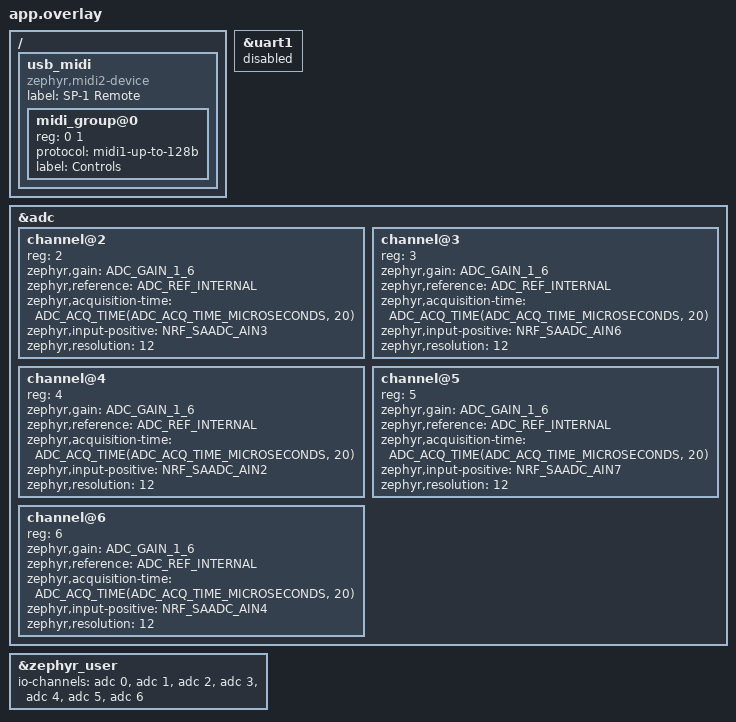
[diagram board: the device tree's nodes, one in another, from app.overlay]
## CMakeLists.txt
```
cmake_minimum_required(VERSION 3.20.0)
find_package(Zephyr REQUIRED HINTS $ENV{ZEPHYR_BASE})
project(sp1-remote)

# Provides sample_usbd_init_device() and friends. Required: with
# CONFIG_CDC_ACM_SERIAL_INITIALIZE_AT_BOOT=n nothing brings USB up on its
# own, so without this the diagnostic console never enumerates. The looper
# does the same at its firmware/CMakeLists.txt:4.
include(${ZEPHYR_BASE}/samples/subsys/usb/common/common.cmake)

target_sources(app PRIVATE
  src/main.c
  src/board_io.c
  src/controls.c
  src/buttons.c
  src/profile.c
  src/txqueue.c
  src/presets.c
  src/perform.c
  src/presets_flash.c
  src/midi_tx.c
  src/midi_trs.c
  src/midi_usb.c
  src/config_console.c
)
```

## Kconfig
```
# SP-1 Remote application Kconfig.
#
# Pulls in the common USB sample options (CONFIG_SAMPLE_USBD_VID / PID /
# PRODUCT / MANUFACTURER / MAX_POWER) consumed by the sample_usbd_init.c
# device_next bring-up helper that CMakeLists.txt includes, then the standard
# Zephyr tree. Without this source line those symbols are undefined and the
# build aborts on Kconfig warnings.

source "samples/subsys/usb/common/Kconfig.sample_usbd"

source "Kconfig.zephyr"
```

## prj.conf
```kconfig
# ---- BOOTLOADER SAFETY ----------------------------------------------------
# The SP-1 has no reset pin. The watchdog and a clean SYSTEM_OFF path are the
# only ways back to the bootloader, so these are not optional.
CONFIG_WATCHDOG=y
CONFIG_REBOOT=y
CONFIG_POWEROFF=y
# HW_STACK_PROTECTION uses the ARM MPU as a stack guard. It excludes
# STACK_SENTINEL (which depends on !MPU_STACK_GUARD), and the hardware guard
# is the stronger of the two: it faults on the access rather than noticing a
# corrupted canary afterwards.
CONFIG_HW_STACK_PROTECTION=y
CONFIG_ASSERT=n
CONFIG_LOG=n

CONFIG_CLOCK_CONTROL=y
CONFIG_CLOCK_CONTROL_NRF_K32SRC_SYNTH=y

# ---- Panel --------------------------------------------------------------
# ADC for the two button ladders and the four faders; GPIO for the LEDs,
# the charger control lines and the button rail.
CONFIG_ADC=y
CONFIG_GPIO=y

# The LED soft-PWM ISR must not be delayed by kernel locks or other
# interrupts: edge jitter at a low duty cycle is visible as flicker.
CONFIG_ZERO_LATENCY_IRQS=y

# ---- USB CDC diagnostic console -----------------------------------------
# Nothing brings USB up by itself with the device_next stack and
# INITIALIZE_AT_BOOT=n, so board_io_init() calls sample_usbd_init_device()
# and usbd_enable(). The helper comes from the include in CMakeLists.txt.
CONFIG_PRINTK=y
CONFIG_SERIAL=y
CONFIG_CONSOLE=y
CONFIG_UART_CONSOLE=y
CONFIG_UART_LINE_CTRL=y
CONFIG_UART_INTERRUPT_DRIVEN=y
CONFIG_USB_DEVICE_STACK_NEXT=y
CONFIG_USBD_CDC_ACM_CLASS=y
CONFIG_CDC_ACM_SERIAL_INITIALIZE_AT_BOOT=n
CONFIG_HWINFO=y

# ---- USB MIDI 2, the second transmit sink ----
# Composite with the CDC console. sp1-midi ships exactly this pair, and the
# looper independently proves composite works on this hardware (UAC2 + CDC).
CONFIG_USBD_MIDI2_CLASS=y
CONFIG_SAMPLE_USBD_MANUFACTURER="Morten Wagner"
CONFIG_SAMPLE_USBD_PRODUCT="SP-1 Remote"
# 100 mA in 2 mA units. The puck runs from its own battery and barely sips
# the bus; iOS hosts reject accessories claiming more over a camera adapter.
CONFIG_SAMPLE_USBD_MAX_POWER=50

# ---- Preset storage (Phase 7) -------------------------------------------
# FLASH_PAGE_LAYOUT is needed by flash_area_erase. On nRF52840 the ARM MPU
# blocks runtime flash writes unless MPU_ALLOW_FLASH_WRITE is set: without
# it the first save faults instead of failing cleanly.
CONFIG_FLASH=y
CONFIG_FLASH_MAP=y
CONFIG_FLASH_PAGE_LAYOUT=y
CONFIG_MPU_ALLOW_FLASH_WRITE=y

CONFIG_MAIN_STACK_SIZE=2048
```

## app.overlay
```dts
/*
 * ADC channels for the four faders and the battery divider. Channels 0 and
 * 1 (the button ladders) come from the board file; these five extend the
 * same list, and firmware/src/board_io.c consumes ALL SEVEN BY INDEX via
 * DT_PATH(zephyr_user). Reordering this list silently reassigns faders.
 *
 * Vendored from sp1-tape-looper firmware/app.overlay (MIT). The gain,
 * reference and acquisition time must stay identical to the board file's
 * channels 0-1: the button decode thresholds in board_io.c are calibrated
 * raw values under exactly this configuration.
 *
 * TRS MIDI: data on the tip via uart1 (below); the ring's current source is
 * P0.23, driven directly from firmware/src/midi_trs.c.
 */

/ {
	/* USB MIDI 2 device, alongside the CDC console: a composite. Node
	 * shape from ericlewis/sp1-midi app.overlay (MIT). One group is
	 * enough; the surface is a single controller. */
	usb_midi: usb_midi {
		compatible = "zephyr,midi2-device";
		status = "okay";
		#address-cells = <1>;
		#size-cells = <1>;
		label = "SP-1 Remote";

		midi_group@0 {
			reg = <0 1>;
			protocol = "midi1-up-to-128b";
			label = "Controls";
		};
	};
};

/* ---- TRS MIDI out: two hardware UARTEs, driven directly, TX only ----
 *
 * TRS Type A, data on the TIP. The SP-1 wires TWO pins to the tip, P0.20
 * and P0.17, each presumably through its own resistor ("paralleled" in the
 * looper's notes on TimK's schematic), and the ring's current source is a
 * PNP on P0.23. All three live in firmware/src/midi_trs.c, which programs
 * UARTE1 (P0.20) and UARTE0 (P0.17) at register level and starts them in
 * the same instant, so both tip pins carry one waveform.
 *
 * Why both pins (2026-11-06): with the ring source on, one pin was enough
 * for the Midihub but not for the Tiliqua's H11L1 opto, which needs more
 * current; a Pro-2 (5 V MIDI) lights the Tiliqua fine. feldd's notes
 * foresaw it: "A second tip pin (P0.17, a parallel current copy) is only
 * needed if one pin cannot drive the MIDI opto".
 *
 * Both UARTs are therefore DISABLED here, so no Zephyr driver owns them.
 * uart0 is the Bluetooth module's UART and is already off in the board
 * file; nothing in this firmware uses Bluetooth. */
&uart1 {
	status = "disabled";
};

&adc {
	channel@2 { reg = <2>; zephyr,gain = "ADC_GAIN_1_6"; zephyr,reference = "ADC_REF_INTERNAL";
		zephyr,acquisition-time = <ADC_ACQ_TIME(ADC_ACQ_TIME_MICROSECONDS, 20)>;
		zephyr,input-positive = <NRF_SAADC_AIN3>; zephyr,resolution = <12>; };   /* Fader 1 P0.05 */
	channel@3 { reg = <3>; zephyr,gain = "ADC_GAIN_1_6"; zephyr,reference = "ADC_REF_INTERNAL";
		zephyr,acquisition-time = <ADC_ACQ_TIME(ADC_ACQ_TIME_MICROSECONDS, 20)>;
		zephyr,input-positive = <NRF_SAADC_AIN6>; zephyr,resolution = <12>; };   /* Fader 2 P0.30 */
	channel@4 { reg = <4>; zephyr,gain = "ADC_GAIN_1_6"; zephyr,reference = "ADC_REF_INTERNAL";
		zephyr,acquisition-time = <ADC_ACQ_TIME(ADC_ACQ_TIME_MICROSECONDS, 20)>;
		zephyr,input-positive = <NRF_SAADC_AIN2>; zephyr,resolution = <12>; };   /* Fader 3 P0.04 */
	channel@5 { reg = <5>; zephyr,gain = "ADC_GAIN_1_6"; zephyr,reference = "ADC_REF_INTERNAL";
		zephyr,acquisition-time = <ADC_ACQ_TIME(ADC_ACQ_TIME_MICROSECONDS, 20)>;
		zephyr,input-positive = <NRF_SAADC_AIN7>; zephyr,resolution = <12>; };   /* Fader 4 P0.31 */
	channel@6 { reg = <6>; zephyr,gain = "ADC_GAIN_1_6"; zephyr,reference = "ADC_REF_INTERNAL";
		zephyr,acquisition-time = <ADC_ACQ_TIME(ADC_ACQ_TIME_MICROSECONDS, 20)>;
		zephyr,input-positive = <NRF_SAADC_AIN4>; zephyr,resolution = <12>; };   /* Battery level P0.28 (divider, per SP-1-dev wiki) */
};
&zephyr_user {
	io-channels = <&adc 0>, <&adc 1>, <&adc 2>, <&adc 3>, <&adc 4>, <&adc 5>, <&adc 6>;
};
```

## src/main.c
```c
/* SP-1 Remote: a 4-fader / 4-button TRS MIDI controller.
 *
 * Phase 2 skeleton: boots, shows life, charges, powers down cleanly, and can
 * always be recovered. No MIDI yet, deliberately. Nothing is worth debugging
 * on top of an uncertain bring-up.
 *
 * BOOTLOADER SAFETY (the SP-1 "BIG FIVE", inherited from sp1-tape-looper):
 *   the app lives at 0x20000; the watchdog is fed every control pass;
 *   bootloader-owned clocks and peripherals are not re-initialised;
 *   SYSTEM_OFF is the only power-down path; RESETREAS is cleared at boot and
 *   again before SYSTEM_OFF. There is no reset pin on this hardware.
 *
 * The escape hatch below is the reason this firmware can be flashed onto
 * scarce hardware with a straight face: holding Track 1 + Track 4 resets
 * into the bootloader even if everything else here is wedged.
 */

#include <zephyr/kernel.h>
#include <string.h>
#include "board_io.h"
#include "midi_trs.h"
#include "midi_tx.h"
#include "controls.h"
#include "profile.h"
#include "buttons.h"
#include "presets.h"
#include "perform.h"
#include "config_console.h"

#define SP1_DIAG 1

#define CONTROL_PERIOD_MS 5
#define POWER_HOLD_MS     2500

/* Track 1 + Track 4 read as their own ADC band, ~1325, which sits INSIDE
 * track 4's decode range (950..1500). It must therefore be tested BEFORE
 * decoding buttons, or the recovery gesture reads as a track-4 press.
 * Source: sp1-tape-looper main.c:6964-6981. */
#define COMBO14_LO       1280
#define COMBO14_HI       1390
#define COMBO14_HOLD_MS  1200

/* Consecutive failed ADC reads tolerated before the ladder reports "nothing
 * pressed". Holding the last value forever would turn a transient failure
 * into a phantom press. */
#define LADDER_ERR_LIMIT 10

profile_t              g_profile;      /* the live, editable mapping */
static perform_t       g_perf;         /* songs, chords, held stutters  */
static fader_state_t   g_fader[PROFILE_NUM_FADERS];
static btn_state_t     g_btn[PROFILE_NUM_BUTTONS];
static button_engine_t g_eng;
static int             g_last_raw;      /* for the diagnostic line only */
static uint32_t        g_save_blink_until;
static bool            g_save_ok;

/* Read the track ladder, handle the recovery combo, and debounce.
 *
 * The Track 1 + Track 4 combo reads ~1325, which sits INSIDE track 4's
 * decode band (950..1500), so it MUST be tested before decoding or the
 * rescue gesture fires a preset save instead of reaching the bootloader.
 * Measured on pop: an isolated track-4 press peaks at 1234 and the combo
 * lands at 1322-1329, so the 1280 boundary has 46 counts of margin.
 *
 * Debounce: the buttons share one noisy resistor ladder, so a single read
 * at a band edge can name the wrong button. Commit only after three
 * agreeing passes, as the looper does (main.c:7513-7519).
 *
 * ADC errors are tolerated briefly, then reported as "nothing pressed":
 * holding the last value forever would turn a transient failure into a
 * phantom press, which for a toggle means freeze flipping on its own. */
/* Snapshot what the puck last SENT, which is all it knows: MIDI here is
 * one-way, so anything changed from Push 3 or the synth's own menu is not
 * captured. Accepted in the design. Freeze is excluded by the profile's
 * capture list, since a scene should not re-trigger a live gesture.
 *
 * Every write is bounds-checked individually, not just the outer loop: a
 * generic profile may map one CC to two faders, and then a single capture
 * entry produces two messages. */
static int snapshot_surface(const profile_t *prof, cc_msg_t *out, int out_max)
{
	int n = 0;

	for (int c = 0; c < prof->preset_capture_len; c++) {
		uint8_t cc = prof->preset_capture[c];

		for (int f = 0; f < PROFILE_NUM_FADERS && n < out_max; f++) {
			if (prof->fader[f].cc == cc && g_fader[f].have_sent) {
				out[n].channel = prof->fader[f].channel;
				out[n].cc      = cc;
				out[n].value   = g_fader[f].last_sent;
				n++;
			}
		}
		for (int b = 0; b < PROFILE_NUM_BUTTONS && n < out_max; b++) {
			const button_cfg_t *cfg = &prof->button[b];

			if (cfg->mode == BTN_MODE_CYCLE && cfg->cc == cc) {
				out[n].channel = cfg->channel;
				out[n].cc      = cc;
				out[n].value   =
					cfg->steps[button_engine_step_index(&g_eng, b)];
				n++;
			}
		}
		if (n >= out_max) {
			break;
		}
	}
	return n;
}

/* preset_store_save takes BOTH slots, and the engine holds them separately,
 * so the bank has to be assembled. Saving one slot alone would blank the
 * other. */
static bool persist_all_slots(void)
{
	preset_bank_t bank;

	memset(&bank, 0, sizeof(bank));
	for (int sl = 0; sl < BUTTON_MAX_PRESET_SLOTS; sl++) {
		const preset_slot_t *ps = button_engine_get_preset(&g_eng, sl);

		if (ps != NULL) {
			bank.slot[sl] = *ps;
		}
	}
	return preset_store_save(&bank);
}

/* A recall moves the synth out from under the faders and the cycle button.
 * Without this the next ADC pass sees a fader where it was, decides that
 * differs, and instantly undoes the scene; and shimmer's LED would lie. */
static void resync_after_recall(const profile_t *prof,
				const cc_msg_t *msgs, int n)
{
	for (int m = 0; m < n; m++) {
		for (int f = 0; f < PROFILE_NUM_FADERS; f++) {
			if (prof->fader[f].cc == msgs[m].cc &&
			    prof->fader[f].channel == msgs[m].channel) {
				fader_arm_pickup(&g_fader[f], msgs[m].value);
			}
		}
		for (int b = 0; b < PROFILE_NUM_BUTTONS; b++) {
			if (prof->button[b].mode == BTN_MODE_CYCLE &&
			    prof->button[b].cc == msgs[m].cc &&
			    prof->button[b].channel == msgs[m].channel) {
				button_engine_sync_cycle(&g_eng, b, msgs[m].value);
			}
		}
	}
}

static int debounced_track_button(void)
{
	static int     committed = -1, candidate = -1, count;
	static int64_t combo14_t = -1;
	static int     err_run;

	int raw = board_io_read_track_ladder();

	g_last_raw = raw;

	if (raw < 0) {
		if (++err_run < LADDER_ERR_LIMIT) {
			return committed;
		}
		committed = candidate = -1;
		count = 0;
		combo14_t = -1;
		return committed;
	}
	err_run = 0;

	if (raw >= COMBO14_LO && raw <= COMBO14_HI) {
		if (combo14_t < 0) {
			combo14_t = k_uptime_get();
		} else if (k_uptime_get() - combo14_t >= COMBO14_HOLD_MS) {
			board_io_enter_dfu();          /* does not return */
		}
		committed = candidate = -1;        /* never a button in-band */
		count = 0;
		return committed;
	}
	combo14_t = -1;

	int b = board_io_decode_track_button(raw);

	if (b == committed) {
		count = 0;
	} else if (b == candidate) {
		if (++count >= 3) {
			committed = b;
			count = 0;
		}
	} else {
		candidate = b;
		count = 1;
	}
	return committed;
}

/* The vol/rocker ladder, the same three-pass debounce as the track ladder
 * (transplanted from Syrup). -1 none, 0 rocker down, 1 vol-down, 2 rocker
 * up, 3 vol-up. */
static int g_last_vol_raw;

static int debounced_vol_button(void)
{
	static int committed = -1, candidate = -1, count;
	static int err_run;

	int raw = board_io_read_vol_ladder();

	g_last_vol_raw = raw;

	if (raw < 0) {
		if (++err_run < LADDER_ERR_LIMIT) {
			return committed;
		}
		committed = candidate = -1;
		count = 0;
		return committed;
	}
	err_run = 0;

	int b = board_io_decode_vol(raw);

	if (b == committed) {
		count = 0;
	} else if (b == candidate) {
		if (++count >= 3) {
			committed = b;
			count = 0;
		}
	} else {
		candidate = b;
		count = 1;
	}
	return committed;
}

int main(void)
{
	/* The live profile is a RAM copy, so it can be edited over the console
	 * and persisted. The compiled-in table is always the fallback: if flash
	 * holds nothing valid, or a stored record is rejected, the puck comes
	 * up with the shipped mapping rather than nothing. */
	g_profile = profile_popgoblin_default;
	(void)profile_store_load(&g_profile);

	const profile_t *prof = &g_profile;

	board_io_init();
	midi_tx_init();
	config_console_init();
	button_engine_init(&g_eng, prof);
	perform_init(&g_perf, prof->fader[0].channel);

	/* Load stored scenes. Silent: loading must not transmit, the puck
	 * says nothing until a control is touched. */
	{
		preset_bank_t bank;

		if (preset_store_load(&bank)) {
			for (int sl = 0; sl < BUTTON_MAX_PRESET_SLOTS; sl++) {
				button_engine_set_preset(&g_eng, sl,
							 bank.slot[sl].msg,
							 bank.slot[sl].len);
			}
		}
	}

	uint32_t held_since = 0u;

	for (;;) {
		board_io_feed_wdt();
		config_console_poll();

		int pressed = debounced_track_button();

		/* ---- power off on a long function-button hold ----
		 * Timed from uptime, not by adding CONTROL_PERIOD_MS per pass:
		 * the loop's real period is work plus 5 ms, and a diagnostic
		 * pass, a page dump or a flash write all make it longer, so
		 * counting iterations would stretch a nominal 2.5 s hold. */
		if (board_io_function_held()) {
			uint32_t now_ms = (uint32_t)k_uptime_get();

			if (held_since == 0u) {
				held_since = now_ms ? now_ms : 1u;
			} else if ((uint32_t)(now_ms - held_since) >= POWER_HOLD_MS) {
				midi_trs_release();          /* ring source off before SYSTEM_OFF latches it */
				board_io_power_off();       /* does not return */
			}
		} else {
			held_since = 0u;
		}

		/* ---- panel readout ----
		 * These LEDs show the PUCK's own state. MIDI here is one-way and
		 * there is no readback, so nothing on this panel can prove the
		 * synth agrees: it equals the synth only while the puck is the
		 * authoritative controller for these CCs.
		 *
		 * The side column mirrors each fader's last sent value. The
		 * renderer is a shadow mask with a global dim, not per-LED PWM,
		 * so board_io_led_set quantises to three levels: off, ghost, on.
		 * A fader in soft pickup blinks instead, since it is not in
		 * control yet and the performer needs to know. */
		{
			uint32_t now_ms = (uint32_t)k_uptime_get();
			bool     blink  = ((now_ms / 200) & 1) != 0;

			/* Side column: the song number in binary, bottom LED
			 * = bit 0 (Syrup's preset code). A PLAY press flashes the
			 * whole column. A fader in soft pickup still blinks its
			 * LED, since it is not in control yet. */
			uint8_t code = perform_side_code(&g_perf);
			bool    flash = perform_flash(&g_perf, now_ms);

			for (int i = 0; i < PROFILE_NUM_FADERS; i++) {
				unsigned from_bottom = (unsigned)(PROFILE_NUM_FADERS - 1 - i);
				uint8_t level;

				if (fader_pickup_armed(&g_fader[i])) {
					level = blink ? 255u : 0u;
				} else if (flash) {
					level = 255u;
				} else {
					level = ((code >> from_bottom) & 1u) ? 255u : 0u;
				}
				board_io_led_set(i, level);
			}

			/* Track row: freeze latched, shimmer off or not, and whether
			 * each preset slot holds a scene. */
			/* A save confirms itself: three fast blinks across the
			 * track row when it worked, a single long one when the
			 * write failed. A silent failure here would be invisible
			 * until the scene did not come back. */
			if (now_ms < g_save_blink_until) {
				bool on = g_save_ok ? (((now_ms / 100) & 1) != 0)
						    : true;

				for (int b = 0; b < PROFILE_NUM_BUTTONS; b++) {
					board_io_track_led_set(b, on);
				}
			} else {
			for (int b = 0, h = 0; b < PROFILE_NUM_BUTTONS; b++) {
				const button_cfg_t *c = &prof->button[b];
				bool on = false;

				if (c->mode == BTN_MODE_TOGGLE) {
					on = button_engine_is_latched(&g_eng, b);
				} else if (c->mode == BTN_MODE_CYCLE) {
					on = button_engine_step_index(&g_eng, b) != 0;
				} else if (c->mode == BTN_MODE_HOLD) {
					on = perform_is_held(&g_perf, h++);
				} else if (c->mode == BTN_MODE_PRESET) {
					const preset_slot_t *ps =
						button_engine_get_preset(&g_eng, c->preset_slot);
					on = ps != NULL && ps->len > 0;
				}
				board_io_track_led_set(b, on);
			}
			}
		}

#if SP1_DIAG
		static int diag_div;
		if (!g_diag_quiet && ++diag_div >= 40) {                 /* every 200 ms */
			diag_div = 0;
			printk("vol=%4d song=%u  ", g_last_vol_raw, g_perf.song + 1u);
			printk("f0=%4d f1=%4d f2=%4d f3=%4d  lad=%4d btn=%d  "
			       "batt=%4d usb=%d chg=%d  "
			       "push=%u drain=%u usbtx=%u rdy=%d\n",
			       board_io_read_fader(0), board_io_read_fader(1),
			       board_io_read_fader(2), board_io_read_fader(3),
			       g_last_raw, board_io_decode_track_button(g_last_raw),
			       board_io_read_battery(),
			       board_io_usb_present() ? 1 : 0,
			       board_io_charging() ? 1 : 0,
			       midi_tx_pushed(), midi_tx_drained(),
			       midi_tx_usb_sent(), midi_tx_usb_ready() ? 1 : 0);
		}
#endif

		/* ---- faders -> CC, through the coalescing queue ----
		 * All four are read every pass. The looper round-robins them
		 * only because its blocking ADC reads competed with an eMMC
		 * streamer; nothing competes here. */
		for (int i = 0; i < PROFILE_NUM_FADERS; i++) {
			uint8_t v;

			if (fader_update(&g_fader[i], board_io_read_fader(i), &v)) {
				midi_tx_send((cc_msg_t){ prof->fader[i].channel,
							 prof->fader[i].cc, v });
			}
		}

		/* ---- buttons -> CC lists ----
		 * Only one ladder button can be read at a time by construction,
		 * so the surface has no chords. Toggle and cycle act on the
		 * press; preset waits for the release, because a press alone
		 * cannot yet be told apart from the start of a hold-to-save. */
		{
			uint32_t now = (uint32_t)k_uptime_get();
			cc_msg_t msgs[PROFILE_MAX_CAPTURE];

			/* PLAY = next chord (the loop engine). Function + PLAY
			 * still dumps the storage page (Task 7.0) for diagnosis. */
			static bool play_was_down;
			bool play_down = (pressed == 4);

			if (play_down && !play_was_down) {
				if (board_io_function_held()) {
					(void)midi_tx_idle(200);
					preset_store_dump();
				} else if (perform_play(&g_perf, now, msgs) == 1) {
					midi_tx_send(msgs[0]);
				}
			}
			play_was_down = play_down;

			/* Rocker = song -/+ (Program Change), on the press. */
			static int vol_was = -1;
			int vol = debounced_vol_button();

			if (vol != vol_was && (vol == 0 || vol == 2)) {
				if (perform_rocker(&g_perf, vol == 2 ? +1 : -1, msgs) == 1) {
					midi_tx_send(msgs[0]);
				}
			}
			vol_was = vol;

			/* Held stutters: 127 on the press, repeated every 100 ms,
			 * 0 on the release. */
			for (int b = 0, h = 0; b < PROFILE_NUM_BUTTONS; b++) {
				if (prof->button[b].mode != BTN_MODE_HOLD) {
					continue;
				}
				if (perform_hold(&g_perf, h++, pressed == b, now, msgs) == 1) {
					midi_tx_send(msgs[0]);
				}
			}

			for (int i = 0; i < PROFILE_NUM_BUTTONS; i++) {
				uint8_t ev = btn_update(&g_btn[i], pressed == i, now);

				if (!ev) {
					continue;
				}

				int n = button_engine_event(&g_eng, i, ev, msgs,
							   (int)ARRAY_SIZE(msgs));

				if (n == BUTTON_ACTION_SAVE_PRESET) {
					cc_msg_t snap[PROFILE_MAX_CAPTURE];
					int slot = button_engine_pending_save_slot(&g_eng);
					int sn = snapshot_surface(prof, snap,
								  (int)ARRAY_SIZE(snap));

					button_engine_set_preset(&g_eng, slot, snap, sn);
					/* Let the wire go quiet first: a flash
					 * write stalls the CPU long enough to
					 * corrupt a bit-banged MIDI byte. */
					(void)midi_tx_idle(200);
					g_save_ok = persist_all_slots();
					g_save_blink_until = now + 900u;
					continue;
				}
				for (int k = 0; k < n; k++) {
					midi_tx_send(msgs[k]);
				}
				if (n > 0) {
					resync_after_recall(prof, msgs, n);
				}
			}
		}

		k_msleep(CONTROL_PERIOD_MS);
	}
	return 0;
}
```

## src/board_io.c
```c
/* SP-1 panel hardware.
 *
 * Transplanted from chattock/sp1-tape-looper firmware/src/main.c (MIT). Each
 * block below names the source line range it came from. What is NOT here, on
 * purpose: the audio path, the eMMC driver, the codecs and the looper engine.
 * This firmware has no audio, which is also why it needs no patched Zephyr.
 *
 * BOOTLOADER SAFETY (the SP-1 "BIG FIVE", main.c:40-44):
 *   the app lives at 0x20000; the watchdog is fed inside every loop;
 *   bootloader-owned clocks and peripherals are not re-initialised;
 *   SYSTEM_OFF is the only power-down path; RESETREAS is cleared at boot and
 *   again before SYSTEM_OFF. There is no reset pin on this hardware, so
 *   board_io_enter_dfu() is the escape hatch when the app itself is wedged.
 */

#include <zephyr/kernel.h>
#include <zephyr/irq.h>
#include <zephyr/device.h>
#include <zephyr/drivers/adc.h>
#include <zephyr/drivers/watchdog.h>
#include <zephyr/usb/usbd.h>
#include <sample_usbd.h>
#include <soc.h>

#include "board_io.h"

/* ---- the 4 centre-row LEDs (main.c:100-105, verified pin map) ---- */
struct led { NRF_GPIO_Type *port; uint32_t pin; };
static const struct led leds[] = {
	{ NRF_P1, 13 }, { NRF_P0, 0 }, { NRF_P1, 12 }, { NRF_P0, 1 },
};
#define NUM_LEDS (sizeof(leds) / sizeof(leds[0]))

/* ---- the 4 TRACK LEDs, directly above buttons 1-4 (main.c:107-110) ---- */
static const struct led track_leds[] = {
	{ NRF_P0, 29 }, { NRF_P0, 26 }, { NRF_P1, 15 }, { NRF_P1, 14 },
};
#define NUM_TRACK_LEDS (sizeof(track_leds) / sizeof(track_leds[0]))

/* 1 = dim rendering (the looper's default), 0 = full brightness. */
static volatile uint8_t g_led_dim = 1;

/* ---- power / function button: P0.27, active-low with pull-up (main.c:121-123) ---- */
#define PWR_PORT        NRF_P0
#define PWR_PIN         27u

/* ---- BQ24232 charger control (main.c:126-129, verified pins) ---- */
#define BQ_PORT         NRF_P0
#define BQ_NCE_PIN      21u   /* charge enable, ACTIVE-LOW: drive low = charging on */
#define BQ_NCHG_PIN     22u   /* charge status, open-drain, LOW = charging now      */
#define BQ_NPGOOD_PIN   24u   /* power good,    open-drain, LOW = USB power present */

/* ---- button ladder rail (main.c:145-146) ----
 * The PLAY/track and Vol/rocker buttons are resistor ladders read on the
 * SAADC. They are only powered when BTN_COM is driven high. */
#define BTN_COM_PORT    NRF_P1
#define BTN_COM_PIN     10u

/* ---- ADC channels (main.c:143-156) ----
 * Consumed BY INDEX. The order must match firmware/app.overlay. */
static const struct adc_dt_spec adc_ladder[] = {
	ADC_DT_SPEC_GET_BY_IDX(DT_PATH(zephyr_user), 0),  /* AIN0: PLAY + tracks   */
	ADC_DT_SPEC_GET_BY_IDX(DT_PATH(zephyr_user), 1),  /* AIN1: Vol + FWD/RWD   */
	ADC_DT_SPEC_GET_BY_IDX(DT_PATH(zephyr_user), 2),  /* AIN3: Fader 1         */
	ADC_DT_SPEC_GET_BY_IDX(DT_PATH(zephyr_user), 3),  /* AIN6: Fader 2         */
	ADC_DT_SPEC_GET_BY_IDX(DT_PATH(zephyr_user), 4),  /* AIN2: Fader 3         */
	ADC_DT_SPEC_GET_BY_IDX(DT_PATH(zephyr_user), 5),  /* AIN7: Fader 4         */
	ADC_DT_SPEC_GET_BY_IDX(DT_PATH(zephyr_user), 6),  /* AIN4: battery divider */
};
#define LAD_TRACKS 0
#define LAD_VOL    1
#define LAD_FADER0 2     /* faders are ladder indices 2..5 */
#define LAD_BATT   6
#define NUM_LADDERS (sizeof(adc_ladder) / sizeof(adc_ladder[0]))

#define WDT_NODE DT_ALIAS(watchdog0)
static const struct device *const wdt = DEVICE_DT_GET(WDT_NODE);

static uint32_t g_resetreas;
static int16_t  adc_sample;

/* ======================================================================
 *  ADC
 * ====================================================================== */

/* Oversampled ladder read (main.c:192-208, which averaged 2).
 *
 * Raised to 4 after measuring pop: resting jitter was 4 to 7 counts
 * peak-to-peak, several times the plus-or-minus 1 the looper's comment
 * claims. The looper capped this at 2 because its blocking ADC reads
 * competed with an eMMC streamer and stole the margin a recording needed.
 * This firmware has no audio and no storage engine, so the CPU is free:
 * averaging 4 halves the noise for roughly 0.5 ms per control pass.
 *
 * Returns -1 on error: callers treat <0 as "hold the last value". */
static int ladder_read(const struct adc_dt_spec *spec)
{
	struct adc_sequence seq = {
		.buffer      = &adc_sample,
		.buffer_size = sizeof(adc_sample),
	};
	if (adc_sequence_init_dt(spec, &seq) < 0) {
		return -1;
	}
	int32_t acc = 0;
	for (int i = 0; i < 4; i++) {
		if (adc_read_dt(spec, &seq) < 0) {
			return -1;
		}
		acc += adc_sample;
	}
	return (int)(acc / 4);
}

int board_io_read_fader(int idx)
{
	if (idx < 0 || idx >= BOARD_NUM_FADERS) {
		return -1;
	}
	return ladder_read(&adc_ladder[LAD_FADER0 + idx]);
}

int board_io_read_track_ladder(void)
{
	return ladder_read(&adc_ladder[LAD_TRACKS]);
}

int board_io_read_battery(void)
{
	return ladder_read(&adc_ladder[LAD_BATT]);
}

bool board_io_usb_present(void)
{
	return (BQ_PORT->IN & (1u << BQ_NPGOOD_PIN)) == 0u;   /* low = present */
}

bool board_io_charging(void)
{
	return (BQ_PORT->IN & (1u << BQ_NCHG_PIN)) == 0u;     /* low = charging */
}

/* Transplanted from main.c:5098-5107. These thresholds are calibrated raw
 * values under the exact ADC configuration in the board files and
 * app.overlay: gain 1/6, 0.6 V internal reference, 20 us acquisition,
 * 12-bit. Do not change one without re-measuring the other.
 *
 * Note the Track 1 + Track 4 combo reads ~1325, INSIDE the track-4 band
 * below. Callers must check that band BEFORE calling this, or the recovery
 * gesture decodes as a track-4 press. See main.c:6964-6981. */
int board_io_decode_track_button(int v)
{
	if (v <  110) return -1;   /* none           */
	if (v <  300) return 0;    /* track 1, ~213  */
	if (v <  560) return 1;    /* track 2, ~403  */
	if (v <  950) return 2;    /* track 3, ~733  */
	if (v < 1500) return 3;    /* track 4, ~1220 */
	return 4;                  /* play,    ~1823 */
}

int board_io_read_vol_ladder(void)
{
	return ladder_read(&adc_ladder[LAD_VOL]);
}

/* Bands from Syrup (looper main.c:5276-5283). Same ADC configuration as
 * the track ladder. NOT yet re-measured on pop: check the `vol=` value in
 * the diagnostic line if a rocker press does nothing. */
int board_io_decode_vol(int v)
{
	if (v <  200) return -1;   /* none              */
	if (v <  560) return 0;    /* rocker down, ~404 */
	if (v <  950) return 1;    /* vol-down,    ~729 */
	if (v < 1500) return 2;    /* rocker up,  ~1220 */
	return 3;                  /* vol-up,     ~1820 */
}

/* ======================================================================
 *  LEDs: soft PWM (main.c:5121-5240)
 *
 *  The panel LEDs are plain on/off GPIO with no current control, so "dim"
 *  means software PWM: writes go into a shadow mask and a TIMER3 ISR
 *  renders it at a low duty cycle. Single writer (the control loop), the
 *  ISR only reads. ~1 kHz frame is flicker-free.
 *
 *  Adapted from TechnicsOP's dimmed-LED build via the looper (MIT).
 * ====================================================================== */
#define LED_PWM_PERIOD_US   1000u   /* 1 kHz frame                        */
#define LED_PWM_ON_US         52u   /* ~5.2% duty, the track row          */
#define LED_STATUS_ON_US      66u   /* the centre row runs slightly wider */
#define LED_GHOST_FRAME_DIV    5u   /* ghost class: lit 1 frame in N      */
#define LED_PWM_TIMER      NRF_TIMER3
#define LED_PWM_TIMER_IRQn TIMER3_IRQn

/* Every LED pin on each port, for the OFF phase. Must match the two tables
 * above; kept as literals exactly as the looper had them. */
#define LED_ALL_P0 ((1u << 0) | (1u << 1) | (1u << 29) | (1u << 26))
#define LED_ALL_P1 ((1u << 13) | (1u << 12) | (1u << 15) | (1u << 14))

static volatile uint32_t g_led_p0_on, g_led_p1_on;
static volatile uint32_t g_led_p0_ghost, g_led_p1_ghost;
static uint32_t g_led_sta_p0, g_led_sta_p1;   /* centre-row pins */
static uint32_t g_led_trk_p0, g_led_trk_p1;   /* track-row pins  */

/* DIRECT ISR, required for IRQ_ZERO_LATENCY: pure register IO, no kernel
 * calls, returns 0 so it never asks for a reschedule. */
ISR_DIRECT_DECLARE(led_pwm_isr)
{
	if (LED_PWM_TIMER->EVENTS_COMPARE[1]) {          /* period wrap: render */
		LED_PWM_TIMER->EVENTS_COMPARE[1] = 0;
		(void)LED_PWM_TIMER->EVENTS_COMPARE[1];
		static uint32_t gframe;
		uint32_t gdiv = g_led_dim ? 8u : LED_GHOST_FRAME_DIV;
		uint32_t gon  = ((++gframe % gdiv) == 0u);
		uint32_t s0 = g_led_p0_on | (gon ? (g_led_p0_ghost & ~g_led_p0_on) : 0u);
		uint32_t s1 = g_led_p1_on | (gon ? (g_led_p1_ghost & ~g_led_p1_on) : 0u);
		NRF_P0->OUTSET = s0;
		NRF_P0->OUTCLR = LED_ALL_P0 & ~s0;
		NRF_P1->OUTSET = s1;
		NRF_P1->OUTCLR = LED_ALL_P1 & ~s1;
	}
	if (LED_PWM_TIMER->EVENTS_COMPARE[0]) {          /* track-row on-time up */
		LED_PWM_TIMER->EVENTS_COMPARE[0] = 0;
		(void)LED_PWM_TIMER->EVENTS_COMPARE[0];
		if (g_led_dim) {
			NRF_P0->OUTCLR = g_led_trk_p0;
			NRF_P1->OUTCLR = g_led_trk_p1;
		} else {
			NRF_P0->OUTCLR = g_led_p0_ghost & ~g_led_p0_on;
			NRF_P1->OUTCLR = g_led_p1_ghost & ~g_led_p1_on;
		}
	}
	if (LED_PWM_TIMER->EVENTS_COMPARE[2]) {          /* centre-row on-time up */
		LED_PWM_TIMER->EVENTS_COMPARE[2] = 0;
		(void)LED_PWM_TIMER->EVENTS_COMPARE[2];
		if (g_led_dim) {
			NRF_P0->OUTCLR = g_led_sta_p0;
			NRF_P1->OUTCLR = g_led_sta_p1;
		}
	}
	return 0;
}

static void led_cfg_output(const struct led *l)
{
	l->port->PIN_CNF[l->pin] =
		(GPIO_PIN_CNF_DIR_Output    << GPIO_PIN_CNF_DIR_Pos)   |
		(GPIO_PIN_CNF_DRIVE_S0S1    << GPIO_PIN_CNF_DRIVE_Pos) |
		(GPIO_PIN_CNF_INPUT_Connect << GPIO_PIN_CNF_INPUT_Pos);
}

static void led_pwm_init(void)
{
	LED_PWM_TIMER->MODE      = TIMER_MODE_MODE_Timer;
	LED_PWM_TIMER->BITMODE   = TIMER_BITMODE_BITMODE_16Bit;
	LED_PWM_TIMER->PRESCALER = 4;                     /* 16 MHz/16 = 1 us tick */
	LED_PWM_TIMER->CC[0]     = LED_PWM_ON_US;
	LED_PWM_TIMER->CC[1]     = LED_PWM_PERIOD_US;
	LED_PWM_TIMER->CC[2]     = LED_STATUS_ON_US;
	LED_PWM_TIMER->SHORTS    = TIMER_SHORTS_COMPARE1_CLEAR_Msk;
	LED_PWM_TIMER->INTENSET  = TIMER_INTENSET_COMPARE0_Msk |
				   TIMER_INTENSET_COMPARE1_Msk |
				   TIMER_INTENSET_COMPARE2_Msk;

	for (unsigned li = 0; li < NUM_LEDS; li++) {
		led_cfg_output(&leds[li]);
		if (leds[li].port == NRF_P0) {
			g_led_sta_p0 |= (1u << leds[li].pin);
		} else {
			g_led_sta_p1 |= (1u << leds[li].pin);
		}
	}
	for (unsigned li = 0; li < NUM_TRACK_LEDS; li++) {
		led_cfg_output(&track_leds[li]);
		if (track_leds[li].port == NRF_P0) {
			g_led_trk_p0 |= (1u << track_leds[li].pin);
		} else {
			g_led_trk_p1 |= (1u << track_leds[li].pin);
		}
	}

	IRQ_DIRECT_CONNECT(LED_PWM_TIMER_IRQn, 0, led_pwm_isr, IRQ_ZERO_LATENCY);
	irq_enable(LED_PWM_TIMER_IRQn);
	LED_PWM_TIMER->TASKS_CLEAR = 1;
	LED_PWM_TIMER->TASKS_START = 1;
}

static void mask_set(const struct led *l, bool on, bool ghost)
{
	uint32_t bit = (1u << l->pin);
	volatile uint32_t *lit   = (l->port == NRF_P0) ? &g_led_p0_on    : &g_led_p1_on;
	volatile uint32_t *gh    = (l->port == NRF_P0) ? &g_led_p0_ghost : &g_led_p1_ghost;

	if (on)    { *lit |= bit;  } else { *lit &= ~bit; }
	if (ghost) { *gh  |= bit;  } else { *gh  &= ~bit; }
}

void board_io_led_set(int idx, uint8_t level)
{
	if (idx < 0 || idx >= (int)NUM_LEDS) {
		return;
	}
	/* Three levels, see the header: off / ghost / on. */
	mask_set(&leds[idx], level >= 128u, level > 0u && level < 128u);
}

void board_io_track_led_set(int idx, bool on)
{
	if (idx < 0 || idx >= (int)NUM_TRACK_LEDS) {
		return;
	}
	mask_set(&track_leds[idx], on, false);
}

/* Force every LED dark, bypassing the shadow mask. Used immediately before
 * SYSTEM_OFF, which latches the GPIO levels: clearing BOTH rows is what
 * stops lights freezing on into sleep (main.c:5316-5325). */
static void shutdown_leds(void)
{
	g_led_p0_on = g_led_p1_on = 0;
	g_led_p0_ghost = g_led_p1_ghost = 0;
	NRF_P0->OUTCLR = LED_ALL_P0;
	NRF_P1->OUTCLR = LED_ALL_P1;
}

/* ======================================================================
 *  Watchdog (feed main.c:5565-5569, install main.c:5901-5906)
 * ====================================================================== */
void board_io_feed_wdt(void)
{
	for (int ch = 0; ch < 8; ch++) {
		NRF_WDT->RR[ch] = WDT_RR_RR_Reload;
	}
}

/* Install our own watchdog channel, if the hardware will accept one.
 *
 * The BOOTLOADER has already started a watchdog before we run, and on
 * nRF52 a running WDT cannot be reconfigured, so this normally fails. That
 * is fine and expected: board_io_feed_wdt() writes NRF_WDT->RR directly and
 * feeds whichever watchdog is actually running. This function is belt and
 * braces for the case where the bootloader did NOT start one.
 *
 * Two things the original got wrong. The nRF driver requires
 * WDT_FLAG_RESET_SOC; a zero flags field is rejected with -ENOTSUP. And
 * both return codes were discarded, so a rejected install was followed by
 * a setup call on a channel that did not exist, leaving the driver in an
 * invalid state while the comment claimed a working fallback. */
static void wdt_start(void)
{
	if (!device_is_ready(wdt)) {
		printk("wdt: device not ready; relying on the bootloader's\n");
		return;
	}

	struct wdt_timeout_cfg cfg = {
		.window.min = 0,
		.window.max = 4000,
		.callback   = NULL,
		.flags      = WDT_FLAG_RESET_SOC,
	};

	int ch = wdt_install_timeout(wdt, &cfg);

	if (ch < 0) {
		/* Expected when the bootloader's watchdog is already running.
		 * Direct RR writes still feed it, so this is not a problem. */
		printk("wdt: install %d, using the running watchdog\n", ch);
		return;
	}

	int rc = wdt_setup(wdt, 0);

	if (rc < 0) {
		printk("wdt: setup %d\n", rc);
	}
	board_io_feed_wdt();
}

/* ======================================================================
 *  Power button and power-off (main.c:5571-5597, 5664-5735)
 * ====================================================================== */
static void pwr_btn_cfg_input(void)
{
	PWR_PORT->PIN_CNF[PWR_PIN] =
		(GPIO_PIN_CNF_DIR_Input     << GPIO_PIN_CNF_DIR_Pos)  |
		(GPIO_PIN_CNF_PULL_Pullup   << GPIO_PIN_CNF_PULL_Pos) |
		(GPIO_PIN_CNF_INPUT_Connect << GPIO_PIN_CNF_INPUT_Pos);
}

/* Arm the button as the SYSTEM_OFF wake source (sense the low level). */
static void pwr_btn_arm_wake(void)
{
	PWR_PORT->PIN_CNF[PWR_PIN] =
		(GPIO_PIN_CNF_DIR_Input     << GPIO_PIN_CNF_DIR_Pos)  |
		(GPIO_PIN_CNF_PULL_Pullup   << GPIO_PIN_CNF_PULL_Pos) |
		(GPIO_PIN_CNF_INPUT_Connect << GPIO_PIN_CNF_INPUT_Pos)|
		(GPIO_PIN_CNF_SENSE_Low     << GPIO_PIN_CNF_SENSE_Pos);
}

bool board_io_function_held(void)
{
	return (PWR_PORT->IN & (1u << PWR_PIN)) == 0u;   /* low = pressed */
}

void board_io_power_off(void)
{
	/* Shutdown sweep across both rows, then force every LED dark before
	 * SYSTEM_OFF latches the GPIO levels. */
	for (int i = (int)NUM_LEDS - 1; i >= 0; i--) {
		board_io_led_set(i, 0);
		board_io_track_led_set(i, false);
		board_io_feed_wdt();
		k_msleep(80);
	}
	shutdown_leds();

	/* Wait for the finger to leave the button, or the level-sense we are
	 * about to arm would wake us again immediately. */
	while (board_io_function_held()) {
		board_io_feed_wdt();
		k_msleep(20);
	}
	k_msleep(60);              /* debounce the release */
	shutdown_leds();           /* re-assert dark right before sleep */

	pwr_btn_arm_wake();
	board_io_feed_wdt();

	/* NOTE: the looper soft-resets instead when USB is present, because it
	 * has a charge-standby screen to land in. This firmware has none, so it
	 * always powers down. Behaviour while plugged in is a Phase 2 bench
	 * check: confirm the puck goes dark and that holding Track 1 + Track 4
	 * on the next plug still reaches the bootloader. */
	NRF_POWER->RESETREAS = 0xFFFFFFFFu;
	__DSB();
	NRF_POWER->SYSTEMOFF = 1u;
	__DSB();
	for (;;) {
		/* CPU is off; the bootloader takes over on the next press. */
	}
}

/* FAILSAFE recovery (main.c:5743-5753): reset into the bootloader so the
 * puck can ALWAYS be reflashed, including when this firmware is wedged.
 * Shows all four track LEDs as the cue, writes the UF2 magic (harmless if
 * the bootloader ignores it) and resets. The user keeps holding Track 1 +
 * Track 4 through the reset, and the bootloader's own scan enters DFU. */
void board_io_enter_dfu(void)
{
	g_led_p0_on = g_led_p1_on = 0;
	g_led_p0_ghost = g_led_p1_ghost = 0;
	for (unsigned i = 0; i < NUM_TRACK_LEDS; i++) {
		board_io_track_led_set((int)i, true);
	}
	NRF_POWER->GPREGRET = 0x57u;
	__DSB();
	NVIC_SystemReset();
	for (;;) {
	}
}

uint32_t board_io_resetreas(void)
{
	return g_resetreas;
}

/* ======================================================================
 *  Charger (main.c:126-129)
 * ====================================================================== */
static void charger_init(void)
{
	/* nCE is ACTIVE-LOW: drive it low or the puck never charges over
	 * USB-C. Easy to omit, and the symptom (a battery that quietly never
	 * fills) shows up days later. */
	BQ_PORT->OUTCLR = (1u << BQ_NCE_PIN);
	BQ_PORT->PIN_CNF[BQ_NCE_PIN] =
		(GPIO_PIN_CNF_DIR_Output << GPIO_PIN_CNF_DIR_Pos) |
		(GPIO_PIN_CNF_DRIVE_S0S1 << GPIO_PIN_CNF_DRIVE_Pos);
	BQ_PORT->OUTCLR = (1u << BQ_NCE_PIN);

	/* Status lines are open-drain inputs with pull-ups: LOW means active. */
	BQ_PORT->PIN_CNF[BQ_NCHG_PIN] =
		(GPIO_PIN_CNF_DIR_Input     << GPIO_PIN_CNF_DIR_Pos)  |
		(GPIO_PIN_CNF_PULL_Pullup   << GPIO_PIN_CNF_PULL_Pos) |
		(GPIO_PIN_CNF_INPUT_Connect << GPIO_PIN_CNF_INPUT_Pos);
	BQ_PORT->PIN_CNF[BQ_NPGOOD_PIN] =
		(GPIO_PIN_CNF_DIR_Input     << GPIO_PIN_CNF_DIR_Pos)  |
		(GPIO_PIN_CNF_PULL_Pullup   << GPIO_PIN_CNF_PULL_Pos) |
		(GPIO_PIN_CNF_INPUT_Connect << GPIO_PIN_CNF_INPUT_Pos);
}

/* ======================================================================
 *  Init
 * ====================================================================== */
static void controls_init(void)
{
	/* Power the ladder rail before any ADC read (main.c:211-224). */
	BTN_COM_PORT->OUTSET = (1u << BTN_COM_PIN);
	BTN_COM_PORT->PIN_CNF[BTN_COM_PIN] =
		(GPIO_PIN_CNF_DIR_Output    << GPIO_PIN_CNF_DIR_Pos)   |
		(GPIO_PIN_CNF_DRIVE_S0S1    << GPIO_PIN_CNF_DRIVE_Pos) |
		(GPIO_PIN_CNF_INPUT_Connect << GPIO_PIN_CNF_INPUT_Pos);
	BTN_COM_PORT->OUTSET = (1u << BTN_COM_PIN);

	for (unsigned i = 0; i < NUM_LADDERS; i++) {
		if (device_is_ready(adc_ladder[i].dev)) {
			(void)adc_channel_setup_dt(&adc_ladder[i]);
		}
	}
}

/* CDC console. Nothing brings USB up by itself on the device_next stack with
 * CONFIG_CDC_ACM_SERIAL_INITIALIZE_AT_BOOT=n, so the application must. Never
 * blocks: a puck at the rack has no host and must still work. */
static void usb_console_start(void)
{
	struct usbd_context *usbd = sample_usbd_init_device(NULL);

	if (usbd == NULL) {
		return;
	}
	(void)usbd_enable(usbd);
}

void board_io_init(void)
{
	/* The BOOTLOADER has already armed the watchdog with a 4 s window, and
	 * it is running while we initialise. Feed it first and again after the
	 * slowest step, so a slow USB enumeration can never reboot us mid-init.
	 * This is also why the feed writes NRF_WDT->RR directly rather than
	 * going through the Zephyr API: the timeout is not ours to configure. */
	board_io_feed_wdt();

	/* BIG FIVE: latch and clear the reset reason on every boot. */
	g_resetreas = NRF_POWER->RESETREAS;
	NRF_POWER->RESETREAS = 0xFFFFFFFFu;

	pwr_btn_cfg_input();
	led_pwm_init();
	shutdown_leds();
	charger_init();
	controls_init();
	board_io_feed_wdt();

	wdt_start();
	usb_console_start();
	board_io_feed_wdt();
}
```

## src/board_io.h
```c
/* Hardware access for the SP-1 panel.
 *
 * Everything Zephyr-specific and everything register-level lives behind this
 * header, so the logic modules (controls, buttons, profile, txqueue, presets)
 * stay pure C and host-testable.
 *
 * The implementation is transplanted from chattock/sp1-tape-looper (MIT),
 * whose constants are verified on real hardware. Each block in board_io.c
 * carries the source line range it came from. */
#ifndef SP1_BOARD_IO_H
#define SP1_BOARD_IO_H

#include <stdbool.h>
#include <stdint.h>

#define BOARD_NUM_FADERS 4
#define BOARD_NUM_LEDS   4

/* Brings up the LED renderer, the button rail and ADC, the watchdog, the
 * charger, and the USB console. Safe to call once at boot; never blocks
 * waiting for a USB host. */
void board_io_init(void);

/* Feed the watchdog. The bootloader arms a 4 s window and there is no reset
 * pin on this hardware, so every path that can loop must call this. */
void board_io_feed_wdt(void);

/* Raw 12-bit SAADC codes. Negative means the read failed and the caller
 * should hold its last value rather than treat it as a reading. */
int  board_io_read_fader(int idx);
int  board_io_read_track_ladder(void);

/* -1 none, 0..3 track buttons, 4 play. Thresholds are calibrated to the ADC
 * configuration in the board files: see the comment in board_io.c. */
int  board_io_decode_track_button(int raw);

bool board_io_function_held(void);

/* Ladder 2: Vol -/+ and the side rocker (transplanted from Syrup, which
 * took it from the looper's decode_vol). Raw 12-bit code, negative on a
 * failed read. */
int  board_io_read_vol_ladder(void);
/* -1 none, 0 rocker down, 1 vol-down, 2 rocker up, 3 vol-up. */
int  board_io_decode_vol(int raw);

/* Charger telemetry, straight off the BQ24232's open-drain status pins.
 * Both are active LOW at the pin; these return the logical sense. */
bool board_io_usb_present(void);   /* nPGOOD low: bus power is there   */
bool board_io_charging(void);      /* nCHG   low: actively charging    */

/* Raw battery voltage from the on-board divider (AIN4). Relative only:
 * useful for watching it climb, not for a state-of-charge percentage. */
int  board_io_read_battery(void);

/* SYSTEM_OFF. Never returns. Clears RESETREAS first, and leaves the power
 * button armed as the wake source, so the bootloader gets control on the
 * next press. */
void board_io_power_off(void);

/* FAILSAFE: reset into the bootloader from a running app, so the puck can
 * always be reflashed even if this firmware is wedged. Never returns. */
void board_io_enter_dfu(void);

/* Centre-row LEDs.
 *
 * IMPORTANT: the transplanted renderer is a shadow mask plus a global dim
 * setting, NOT per-LED PWM, so this quantises to THREE levels: 0 is off,
 * 1..127 is the "ghost" duty (roughly a fifth of dim), 128..255 is on. The
 * 0..255 signature exists so the Phase 6 code reads naturally and so a
 * future per-LED renderer can be dropped in without touching callers. Do not
 * design a UI that needs more than three levels here without extending the
 * renderer first. */
void board_io_led_set(int idx, uint8_t level);

/* Track-row LEDs, above the four track buttons. On/off only. */
void board_io_track_led_set(int idx, bool on);

/* Reset reason latched at boot, before it was cleared. Diagnostic only. */
uint32_t board_io_resetreas(void);

#endif /* SP1_BOARD_IO_H */
```

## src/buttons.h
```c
/* PURE. The unified button model: every button is "send a list of
 * (channel, cc, value)". Freeze is a one-item toggling list, shimmer is a
 * one-item cycling list, a preset is a short list replayed on the CCs the
 * faders already drive, and BTN_MODE_LIST is an arbitrary configured list.
 * No new CCs, and therefore no synth-side work. */
#ifndef SP1_BUTTONS_H
#define SP1_BUTTONS_H

#include <stdbool.h>
#include <stdint.h>
#include "controls.h"
#include "profile.h"

#define BUTTON_MAX_PRESET_SLOTS 2

/* Returned by button_engine_event instead of a message count. */
#define BUTTON_ACTION_SAVE_PRESET (-1)

typedef struct {
    cc_msg_t msg[PROFILE_MAX_CAPTURE];
    uint8_t  len;
} preset_slot_t;

typedef struct {
    const profile_t *prof;
    bool     latched[PROFILE_NUM_BUTTONS];    /* TOGGLE state */
    uint8_t  step_idx[PROFILE_NUM_BUTTONS];   /* CYCLE position */
    bool     save_armed[PROFILE_NUM_BUTTONS]; /* a hold consumed the release */
    int      pending_save_slot;
    preset_slot_t preset[BUTTON_MAX_PRESET_SLOTS];
} button_engine_t;

void button_engine_init(button_engine_t *e, const profile_t *prof);

/* Feed one button event mask from btn_update. Returns the number of
 * messages written to out, 0 for nothing to send, or
 * BUTTON_ACTION_SAVE_PRESET when the caller must snapshot the surface into
 * button_engine_pending_save_slot(e) and then call button_engine_set_preset.
 *
 * No duration parameter, deliberately. Nothing here reacts to HOW LONG a
 * button was held: TOGGLE and CYCLE act on the press, PRESET acts on the
 * HOLD event (which fires while the button is still down) or on the tap.
 * That is what makes a lost RELEASE harmless. */
int  button_engine_event(button_engine_t *e, int idx, uint8_t ev,
                         cc_msg_t *out, int out_max);

int  button_engine_pending_save_slot(const button_engine_t *e);
void button_engine_set_preset(button_engine_t *e, int slot,
                              const cc_msg_t *msgs, int len);
const preset_slot_t *button_engine_get_preset(const button_engine_t *e, int slot);

/* Re-sync a cycle button after a preset recall replayed its CC: pick the
 * step whose value is nearest what was just sent. Without this the puck's
 * step index, its LED, and the next press all disagree with the synth, and
 * the next snapshot captures the stale step. */
void button_engine_sync_cycle(button_engine_t *e, int idx, uint8_t value);

/* For the LED layer. */
uint8_t button_engine_step_index(const button_engine_t *e, int idx);
bool    button_engine_is_latched(const button_engine_t *e, int idx);

#endif /* SP1_BUTTONS_H */
```

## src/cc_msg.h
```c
/* PURE. One MIDI control-change message.
 *
 * Its own header, and not part of profile.h, purely for build ordering:
 * the transmit queue (Phase 3) needs this type but must not depend on the
 * profile table (Phase 4). Everything downstream gets it transitively. */
#ifndef SP1_CC_MSG_H
#define SP1_CC_MSG_H

#include <stdint.h>

typedef struct {
    uint8_t channel;
    uint8_t cc;
    uint8_t value;
} cc_msg_t;

/* A cc number no Control Change can have (CCs are 0..127). A message with
 * this cc is a Program Change whose program is `value`; the transmit layer
 * turns it into the right bytes. Kept in cc_msg_t so Program Change rides
 * the same coalescing queue as everything else. */
#define CC_MSG_PROGRAM 0x80u

#endif /* SP1_CC_MSG_H */
```

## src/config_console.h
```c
/* Line-based JSON console for editing the control surface over CDC.
 * See config_console.c for the protocol. */
#ifndef SP1_CONFIG_CONSOLE_H
#define SP1_CONFIG_CONSOLE_H

#include <stdbool.h>

/* Enable interrupt-driven RX. Must be called once at boot: Zephyr's CDC ACM
 * does not queue its first USB OUT transfer until RX is enabled, so without
 * this the console receives nothing at all. */
void config_console_init(void);

/* Drain any received bytes and dispatch complete lines. Non-blocking; call
 * once per control pass. */
void config_console_poll(void);

/* Set by the {"t":"quiet"} command. The diagnostic stream is noise to a
 * browser trying to read JSON replies, so the editor turns it off on
 * connect and back on when it disconnects. */
extern bool g_diag_quiet;

#endif /* SP1_CONFIG_CONSOLE_H */
```
